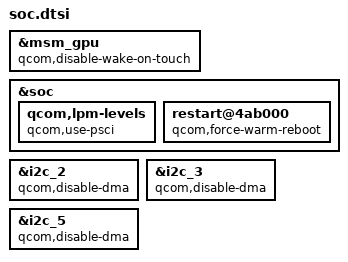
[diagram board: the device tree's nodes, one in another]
&msm_gpu {
	qcom,disable-wake-on-touch;
};

&soc {
	qcom,lpm-levels {
		qcom,use-psci;
	};

	restart@4ab000 {
		qcom,force-warm-reboot;
	};
};

&i2c_2 {
	qcom,disable-dma;
};

&i2c_3 {
	qcom,disable-dma;
};

&i2c_5 {
	qcom,disable-dma;
};
